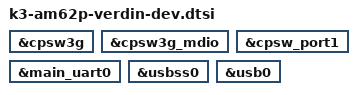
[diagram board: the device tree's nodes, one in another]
// SPDX-License-Identifier: GPL-2.0-or-later OR MIT
/*
 * Copyright 2025 Toradex
 *
 * Common dtsi for Verdin AM62P SoM on Development carrier board
 *
 * https://www.toradex.com/computer-on-modules/verdin-arm-family/ti-am62p
 * https://www.toradex.com/products/carrier-board/verdin-development-board-kit
 */

&cpsw3g {
	status = "okay";
};

/* MDIO, shared by Verdin ETH_1 (On-module PHY) and Verdin ETH_2_RGMII */
&cpsw3g_mdio {
	status = "okay";
};

/* Verdin ETH_1 (On-module PHY) */
&cpsw_port1 {
	status = "okay";
};

/* Verdin UART_3, used as the Linux console */
&main_uart0 {
	status = "okay";
};

/* Verdin USB_1 */
&usbss0 {
	status = "okay";
};

&usb0 {
	status = "okay";
};
